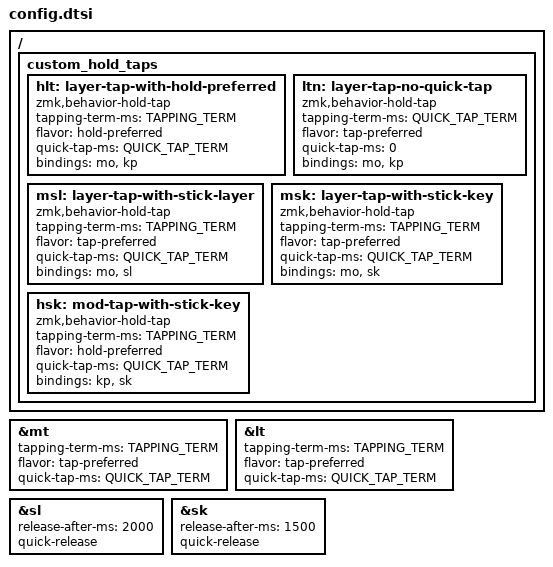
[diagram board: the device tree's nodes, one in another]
// Layers

#define ALPHA1 0
#define ALPHA2 1

// Settings

#define COMBO_TERM_FAST 18
#define COMBO_TERM_SLOW 30

#define COMBO_IDLE_FAST 150
#define COMBO_IDLE_SLOW 50

#define TAPPING_TERM 250
#define QUICK_TAP_TERM 175

#define ADAPTIVE_KEY_TIMEOUT 2000

/*                KEY POSITIONS

  ╭─────────────────────╮ ╭─────────────────────╮
  │ LT4 LT3 LT2 LT1 LT0 │ │ RT0 RT1 RT2 RT3 RT4 │
  │ LM4 LM3 LM2 LM1 LM0 │ │ RM0 RM1 RM2 RM3 RM4 │
  │ LB4 LB3 LB2 LB1 LB0 │ │ RB0 RB1 RB2 RB3 RB4 │
  ╰───────╮ LH2 LH1 LH0 │ │ RH0 RH1 RH2 ╭───────╯
          ╰─────────────╯ ╰─────────────╯ 
  ╭─────────────────────╮ ╭─────────────────────╮
  │  0   1   2   3   4  │ │   5   6   7   8   9 │
  │ 10  11  12  13  14  │ │  15  16  17  18  19 │
  │ 20  21  22  23  24  │ │  25  26  27  28  29 │
  ╰──────╮  30  31  32  │ │  33  34  35 ╭───────╯
         ╰──────────────╯ ╰─────────────╯

*/

#define LT4 0   // left-top row
#define LT3 1
#define LT2 2
#define LT1 3
#define LT0 4  

#define RT0 5   // right-top row
#define RT1 6
#define RT2 7
#define RT3 8
#define RT4 9

#define LM4 10  // left-middle row
#define LM3 11
#define LM2 12
#define LM1 13
#define LM0 14

#define RM0 15  // right-middle row
#define RM1 16
#define RM2 17
#define RM3 18
#define RM4 19

#define LB4 20  // left-bottom row
#define LB3 21
#define LB2 22
#define LB1 23
#define LB0 24

#define RB0 25  // right-bottom row
#define RB1 26
#define RB2 27
#define RB3 28
#define RB4 29

#define LH2 30  // left thumb keys
#define LH1 31
#define LH0 32

#define RH0 33  // right thumb keys
#define RH1 34
#define RH2 35          

&mt {
    tapping-term-ms = <TAPPING_TERM>;
    flavor = "tap-preferred";
    quick-tap-ms = <QUICK_TAP_TERM>;
};

&lt {
    tapping-term-ms = <TAPPING_TERM>;
    flavor = "tap-preferred";
    quick-tap-ms = <QUICK_TAP_TERM>;
};

&sl {
    release-after-ms = <2000>;
    quick-release;
};

&sk {
    release-after-ms = <1500>;
    quick-release;
};

/ {
    custom_hold_taps {

        hlt: layer-tap-with-hold-preferred {
            compatible = "zmk,behavior-hold-tap";
            #binding-cells = <2>;
            tapping-term-ms = <TAPPING_TERM>;
            flavor = "hold-preferred";
            quick-tap-ms = <QUICK_TAP_TERM>;
            bindings = <&mo>, <&kp>;
        };

        ltn: layer-tap-no-quick-tap {
            compatible = "zmk,behavior-hold-tap";
            #binding-cells = <2>;
            tapping-term-ms = <QUICK_TAP_TERM>;
            flavor = "tap-preferred";
            quick-tap-ms = <0>;
            bindings = <&mo>, <&kp>;
        };

        msl: layer-tap-with-stick-layer {
            compatible = "zmk,behavior-hold-tap";
            #binding-cells = <2>;
            tapping-term-ms = <TAPPING_TERM>;
            flavor = "tap-preferred";
            quick-tap-ms = <QUICK_TAP_TERM>;
            bindings = <&mo>, <&sl>;
        };

        msk: layer-tap-with-stick-key {
            compatible = "zmk,behavior-hold-tap";
            #binding-cells = <2>;
            tapping-term-ms = <TAPPING_TERM>;
            flavor = "tap-preferred";
            quick-tap-ms = <QUICK_TAP_TERM>;
            bindings = <&mo>, <&sk>;
        };

        hsk: mod-tap-with-stick-key {
            compatible = "zmk,behavior-hold-tap";
            #binding-cells = <2>;
            tapping-term-ms = <TAPPING_TERM>;
            flavor = "hold-preferred";
            quick-tap-ms = <QUICK_TAP_TERM>;
            bindings = <&kp>, <&sk>;
        };

    };
};
